AUTOSAR XML (schema 00044)
package /E40_Platform_System_SystemPackage/Components
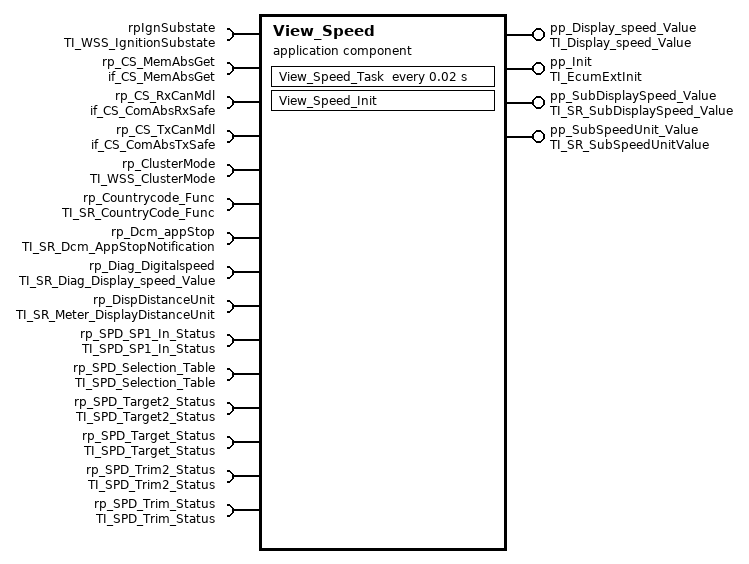
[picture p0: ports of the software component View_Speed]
  application sw component type View_Speed
    4 x provide port:
      pp_Display_speed_Value: nonqueued-sender-com-spec{data-element=Digital_Speed_Value, init-value=constant-reference=View_SpeedDigital_Speed_ValueValue0}, provided-interface=TI_Display_speed_Value
      pp_Init: server-com-spec{operation=Init, queue-length=1}, provided-interface=TI_EcumExtInit
      pp_SubDisplaySpeed_Value: nonqueued-sender-com-spec{data-element=SubDispSpeedVal, init-value=constant-reference=View_SpeedSubDispSpeedValValue0}, provided-interface=TI_SR_SubDisplaySpeed_Value
      pp_SubSpeedUnit_Value: nonqueued-sender-com-spec{data-element=SubSpeedunit, init-value=constant-reference=View_SpeedSubSpeedunitValue0}, provided-interface=TI_SR_SubSpeedUnitValue
    15 x require port:
      rpIgnSubstate: nonqueued-receiver-com-spec{data-element=IgnitionSubstate, init-value=constant-reference=View_SpeedIgnitionSubstateValue0}, required-interface=TI_WSS_IgnitionSubstate
      rp_CS_MemAbsGet: required-interface=if_CS_MemAbsGet
        required-com-specs:
          Get_BsConst_Audio_Element
          Get_BsConst_Communication_Element
          Get_BsConst_EngOffTimer_Element
          Get_BsConst_FuelGauge_Element
          Get_BsConst_OilGauge_Element
          Get_BsConst_PowerGauge_Element
          Get_BsConst_Power_Element
          Get_BsConst_RealTimeClock_Element
          Get_BsConst_ServiceReminder_Element
          Get_BsConst_SpeedoGauge_Element
          Get_BsConst_TachoGauge_Element
          Get_BsConst_TempGauge_Element
          Get_BsConst_TripComputer_Element
          Get_BsConst_Warning_Element
          Get_BsCys_Certicificate_Element
          Get_BsDiag_Dtc_Element
          Get_BsDiag_ErrorRecord_Element
          Get_BsReten_Audio_Element
          Get_BsReten_Communication_Element
          Get_BsReten_Display_Element
          Get_BsReten_Gauges_Element
          Get_BsReten_Illumination_Element
          Get_BsReten_Odometer_Element
          Get_BsReten_Personalization_Element
          Get_BsReten_Power_Element
          Get_BsReten_RealTimeClock_Element
          Get_BsReten_Tripcomputer_Element
          Get_BsReten_Warning_Element
          Get_BsRt_CusDlt_Element
          Get_BsRt_FuelGauge_Element
          Get_BsRt_Illumination_Element
          Get_BsRt_Odometer_Element
          Get_BsRt_OilGauge_Element
          Get_BsRt_Personalization_Element
          Get_BsRt_PowerGauge_Element
          Get_BsRt_RealTimeClock_Element
          Get_BsRt_SpeedoGauge_Element
          Get_BsRt_TachoGauge_Element
          Get_BsRt_TempGauge_Element
          Get_BsRt_TripComputer_Element
          Get_BsRt_Warning_Element
          Get_BsShare_EcuPartNumber_Element
          Get_BsShare_SwUpdFotaFinPrint_Element
          Get_BsShare_SwUpdFotaMode_Element
          Get_BsShare_SwUpdFotaStatus_Element
          Get_BsShare_SwUpdFotadecrypt_Element
          Get_BsShare_SwUpdReflash_Element
          Get_BsShare_VehicleConfig_Element
          Get_BsShare_VisMeet_Element
          Get_RefCys_Certicificate1_Element
          Get_RefCys_Certicificate_Element
          Get_BsShare_VisMeet_EOLEntry_Element
          Get_BsShare_AssemblyManufacturingDate
          Get_BsShare_AssemblyPlantNumber
          Get_BsShare_HWModification
          Get_BsShare_PCBSerialNumber
          Get_BsShare_ProductSerialNumber
          Get_BsShare_SMTManufacturingDate
          Get_BsShare_SMTPlantNumber
          Get_BsShare_VisteonPCBPartNumber
          Get_BsShare_VisteonPartNumber
          Get_BsConst_Temperature_Sensor_Conv_SafeCopy2
          Get_BsConst_Temperature_Sensor_Conv_SafeCopy1
          Get_BsConst_Temperature_Sensor_Conv
          Get_BsConst_Temp_Threshold_Hysteresis_Derating_SafeCopy2
          Get_BsConst_Temp_Threshold_Hysteresis_Derating_SafeCopy1
          Get_BsConst_Temp_Threshold_Hysteresis_Derating
          Get_BsConst_PWM_boost_bypass_duty_SafeCopy2
          Get_BsConst_PWM_boost_bypass_duty_SafeCopy1
          Get_BsConst_PWM_boost_bypass_duty
          Get_BsConst_PCB_Temperature_Sensor_Conv_SafeCopy2
          Get_BsConst_PCB_Temperature_Sensor_Conv_SafeCopy1
          Get_BsConst_PCB_Temperature_Sensor_Conv
          Get_BsConst_Lookup_Curve_HotSpot_Coef_Y_SafeCopy2
          Get_BsConst_Lookup_Curve_HotSpot_Coef_Y_SafeCopy1
          Get_BsConst_Lookup_Curve_HotSpot_Coef_Y
          Get_BsConst_Lookup_Curve_HotSpot_Coef_X_SafeCopy2
          Get_BsConst_Lookup_Curve_HotSpot_Coef_X_SafeCopy1
          Get_BsConst_Lookup_Curve_HotSpot_Coef_X
          Get_BsConst_Display_Illum_Max_Level_SafeCopy2
          Get_BsConst_Display_Illum_Max_Level_SafeCopy1
          Get_BsConst_Display_Illum_Max_Level
          Get_BsConst_Derating_Backlight_Disable_SafeCopy2
          Get_BsConst_Derating_Backlight_Disable_SafeCopy1
          Get_BsConst_Derating_Backlight_Disable
          Get_BsConst_Compensation_Line_Slope_m_SafeCopy2
          Get_BsConst_Compensation_Line_Slope_m_SafeCopy1
          Get_BsConst_Compensation_Line_Slope_m
          Get_BsConst_Compensation_Line_Shift_b_SafeCopy2
          Get_BsConst_Compensation_Line_Shift_b_SafeCopy1
          Get_BsConst_Compensation_Line_Shift_b
          Get_BsConst_BsConst_Illumination_ReservedByte_SafeCopy2
          Get_BsConst_BsConst_Illumination_ReservedByte_SafeCopy1
          Get_BsConst_BsConst_Illumination_ReservedByte
      rp_CS_RxCanMdl: required-interface=if_CS_ComAbsRxSafe
        required-com-specs:
          RxCan_GetSignalValue
          RxCan_GetSignalValueU8Arr
          RxCan_SetSignalInitValue
          RxCan_SetSignalInitValueU8Arr
          RxCan_SignalClearJustRcvdStatus
          RxCan_SignalGetJustRcvdStatus
          RxCan_SignalInvalidProcessingControl
          RxCan_SignalMissingProcessingControl
          RxCan_SignalNRProcessingControl
      rp_CS_TxCanMdl: required-interface=if_CS_ComAbsTxSafe
        required-com-specs:
          TxCan_ClearCanSignalTxConfirmation
          TxCan_GetCanSignalTxConfirmation
          TxCan_SetSignalFromRetentionBuffer
          TxCan_SetSignalValue
          TxCan_SetSignalValueU8Arr
      rp_ClusterMode: nonqueued-receiver-com-spec{data-element=WSSCurrentClusterMode, init-value=constant-reference=View_SpeedWSSCurrentClusterModeValue0}, required-interface=TI_WSS_ClusterMode
      rp_Countrycode_Func: nonqueued-receiver-com-spec{data-element=CountryCode_Func, init-value=constant-reference=View_SpeedCountryCode_FuncValue0}, required-interface=TI_SR_CountryCode_Func
      rp_Dcm_appStop: nonqueued-receiver-com-spec{data-element=AppId, init-value=constant-reference=View_SpeedAppIdValue0}, required-interface=TI_SR_Dcm_AppStopNotification
      rp_Diag_Digitalspeed: nonqueued-receiver-com-spec{data-element=Diag_Digital_Speed_Value, init-value=constant-reference=View_SpeedDiag_Digital_Speed_ValueValue0}, required-interface=TI_SR_Diag_Display_speed_Value
      rp_DispDistanceUnit: nonqueued-receiver-com-spec{data-element=DisplayUnit, init-value=constant-reference=View_SpeedDisplayUnitValue0}, required-interface=TI_SR_Meter_DisplayDistanceUnit
      rp_SPD_SP1_In_Status: nonqueued-receiver-com-spec{data-element=SP1_In_Status, init-value=constant-reference=View_SpeedSP1_In_StatusValue0}, required-interface=TI_SPD_SP1_In_Status
      rp_SPD_Selection_Table: nonqueued-receiver-com-spec{data-element=Speed_Selection_Table, init-value=constant-reference=View_SpeedSpeed_Selection_TableValue0}, required-interface=TI_SPD_Selection_Table
      rp_SPD_Target2_Status: nonqueued-receiver-com-spec{data-element=Spd_Target2_Status, init-value=constant-reference=View_SpeedSpd_Target2_StatusValue0}, required-interface=TI_SPD_Target2_Status
      rp_SPD_Target_Status: nonqueued-receiver-com-spec{data-element=Spd_Target_Status, init-value=constant-reference=View_SpeedSpd_Target_StatusValue0}, required-interface=TI_SPD_Target_Status
      rp_SPD_Trim2_Status: nonqueued-receiver-com-spec{data-element=Spd_Trim2_Status, init-value=constant-reference=View_SpeedSpd_Trim2_StatusValue0}, required-interface=TI_SPD_Trim2_Status
      rp_SPD_Trim_Status: nonqueued-receiver-com-spec{data-element=Spd_Trim_Status, init-value=constant-reference=View_SpeedSpd_Trim_StatusValue0}, required-interface=TI_SPD_Trim_Status
    behavior IB_View_Speed
      operation invoked event OIE_pp_Init_View_Speed_InitTrigByInit: start-on-event=View_Speed_Init, operation=pp_Init.Init
      timing event TEView_Speed_Task: start-on-event=View_Speed_Task, period=0.02
      port-api-options:
        enable-take-address=false, indirect-api=false, port=pp_Display_speed_Value
        enable-take-address=false, indirect-api=false, port=pp_Init
        enable-take-address=false, indirect-api=false, port=pp_SubDisplaySpeed_Value
        enable-take-address=false, indirect-api=false, port=pp_SubSpeedUnit_Value
        enable-take-address=false, indirect-api=false, port=rpIgnSubstate
        enable-take-address=false, indirect-api=false, port=rp_CS_MemAbsGet
        enable-take-address=false, indirect-api=false, port=rp_CS_RxCanMdl
        enable-take-address=false, indirect-api=false, port=rp_CS_TxCanMdl
        enable-take-address=false, indirect-api=false, port=rp_ClusterMode
        enable-take-address=false, indirect-api=false, port=rp_Countrycode_Func
        enable-take-address=false, indirect-api=false, port=rp_Dcm_appStop
        enable-take-address=false, indirect-api=false, port=rp_Diag_Digitalspeed
        enable-take-address=false, indirect-api=false, port=rp_DispDistanceUnit
        enable-take-address=false, indirect-api=false, port=rp_SPD_SP1_In_Status
        enable-take-address=false, indirect-api=false, port=rp_SPD_Selection_Table
        enable-take-address=false, indirect-api=false, port=rp_SPD_Target2_Status
        enable-take-address=false, indirect-api=false, port=rp_SPD_Target_Status
        enable-take-address=false, indirect-api=false, port=rp_SPD_Trim2_Status
        enable-take-address=false, indirect-api=false, port=rp_SPD_Trim_Status
      runnable View_Speed_Init: can-be-invoked-concurrently=true
      runnable View_Speed_Task: can-be-invoked-concurrently=true
        data-receive-point-by-arguments:
          12 x access:
            DRA_rpIgnSubstate_IgnitionSubstate: accessed-variable=rpIgnSubstate.IgnitionSubstate
            DRA_rp_ClusterMode_WSSCurrentClusterMode: accessed-variable=rp_ClusterMode.WSSCurrentClusterMode
            DRA_rp_Countrycode_Func_CountryCode_Func: accessed-variable=rp_Countrycode_Func.CountryCode_Func
            DRA_rp_Dcm_appStop_AppId: accessed-variable=rp_Dcm_appStop.AppId
            DRA_rp_Diag_Digitalspeed_Diag_Digital_Speed_Value: accessed-variable=rp_Diag_Digitalspeed.Diag_Digital_Speed_Value
            DRA_rp_DispDistanceUnit_DisplayUnit: accessed-variable=rp_DispDistanceUnit.DisplayUnit
            DRA_rp_SPD_SP1_In_Status_SP1_In_Status: accessed-variable=rp_SPD_SP1_In_Status.SP1_In_Status
            DRA_rp_SPD_Selection_Table_Speed_Selection_Table: accessed-variable=rp_SPD_Selection_Table.Speed_Selection_Table
            DRA_rp_SPD_Target2_Status_Spd_Target2_Status: accessed-variable=rp_SPD_Target2_Status.Spd_Target2_Status
            DRA_rp_SPD_Target_Status_Spd_Target_Status: accessed-variable=rp_SPD_Target_Status.Spd_Target_Status
            DRA_rp_SPD_Trim2_Status_Spd_Trim2_Status: accessed-variable=rp_SPD_Trim2_Status.Spd_Trim2_Status
            DRA_rp_SPD_Trim_Status_Spd_Trim_Status: accessed-variable=rp_SPD_Trim_Status.Spd_Trim_Status
        data-send-points:
          access DWA_pp_Display_speed_Value_Digital_Speed_Value: accessed-variable=pp_Display_speed_Value.Digital_Speed_Value
          access DWA_pp_SubDisplaySpeed_Value_SubDispSpeedVal: accessed-variable=pp_SubDisplaySpeed_Value.SubDispSpeedVal
          access DWA_pp_SubSpeedUnit_Value_SubSpeedunit: accessed-variable=pp_SubSpeedUnit_Value.SubSpeedunit
        108 x sync call:
          OA_rp_CS_MemAbsGet_Get_BsShare_SwUpdReflash_Element: operation=rp_CS_MemAbsGet.Get_BsShare_SwUpdReflash_Element
          OA_rp_CS_MemAbsGet_Get_BsShare_SwUpdFotaMode_Element: operation=rp_CS_MemAbsGet.Get_BsShare_SwUpdFotaMode_Element
          OA_rp_CS_MemAbsGet_Get_BsShare_SwUpdFotaFinPrint_Element: operation=rp_CS_MemAbsGet.Get_BsShare_SwUpdFotaFinPrint_Element
          OA_rp_CS_MemAbsGet_Get_BsShare_SwUpdFotaStatus_Element: operation=rp_CS_MemAbsGet.Get_BsShare_SwUpdFotaStatus_Element
          OA_rp_CS_MemAbsGet_Get_BsShare_SwUpdFotadecrypt_Element: operation=rp_CS_MemAbsGet.Get_BsShare_SwUpdFotadecrypt_Element
          OA_rp_CS_MemAbsGet_Get_BsShare_EcuPartNumber_Element: operation=rp_CS_MemAbsGet.Get_BsShare_EcuPartNumber_Element
          OA_rp_CS_MemAbsGet_Get_BsShare_VisteonPartNumber: operation=rp_CS_MemAbsGet.Get_BsShare_VisteonPartNumber
          OA_rp_CS_MemAbsGet_Get_BsShare_VisteonPCBPartNumber: operation=rp_CS_MemAbsGet.Get_BsShare_VisteonPCBPartNumber
          OA_rp_CS_MemAbsGet_Get_BsShare_ProductSerialNumber: operation=rp_CS_MemAbsGet.Get_BsShare_ProductSerialNumber
          OA_rp_CS_MemAbsGet_Get_BsShare_PCBSerialNumber: operation=rp_CS_MemAbsGet.Get_BsShare_PCBSerialNumber
          OA_rp_CS_MemAbsGet_Get_BsShare_SMTManufacturingDate: operation=rp_CS_MemAbsGet.Get_BsShare_SMTManufacturingDate
          OA_rp_CS_MemAbsGet_Get_BsShare_AssemblyManufacturingDate: operation=rp_CS_MemAbsGet.Get_BsShare_AssemblyManufacturingDate
          OA_rp_CS_MemAbsGet_Get_BsShare_SMTPlantNumber: operation=rp_CS_MemAbsGet.Get_BsShare_SMTPlantNumber
          OA_rp_CS_MemAbsGet_Get_BsShare_AssemblyPlantNumber: operation=rp_CS_MemAbsGet.Get_BsShare_AssemblyPlantNumber
          OA_rp_CS_MemAbsGet_Get_BsShare_HWModification: operation=rp_CS_MemAbsGet.Get_BsShare_HWModification
          OA_rp_CS_MemAbsGet_Get_BsShare_VisMeet_Element: operation=rp_CS_MemAbsGet.Get_BsShare_VisMeet_Element
          OA_rp_CS_MemAbsGet_Get_BsShare_VisMeet_EOLEntry_Element: operation=rp_CS_MemAbsGet.Get_BsShare_VisMeet_EOLEntry_Element
          OA_rp_CS_MemAbsGet_Get_BsShare_VehicleConfig_Element: operation=rp_CS_MemAbsGet.Get_BsShare_VehicleConfig_Element
          OA_rp_CS_MemAbsGet_Get_BsConst_SpeedoGauge_Element: operation=rp_CS_MemAbsGet.Get_BsConst_SpeedoGauge_Element
          OA_rp_CS_MemAbsGet_Get_BsConst_TachoGauge_Element: operation=rp_CS_MemAbsGet.Get_BsConst_TachoGauge_Element
          OA_rp_CS_MemAbsGet_Get_BsConst_FuelGauge_Element: operation=rp_CS_MemAbsGet.Get_BsConst_FuelGauge_Element
          OA_rp_CS_MemAbsGet_Get_BsConst_TempGauge_Element: operation=rp_CS_MemAbsGet.Get_BsConst_TempGauge_Element
          OA_rp_CS_MemAbsGet_Get_BsConst_PowerGauge_Element: operation=rp_CS_MemAbsGet.Get_BsConst_PowerGauge_Element
          OA_rp_CS_MemAbsGet_Get_BsConst_OilGauge_Element: operation=rp_CS_MemAbsGet.Get_BsConst_OilGauge_Element
          OA_rp_CS_MemAbsGet_Get_BsConst_TripComputer_Element: operation=rp_CS_MemAbsGet.Get_BsConst_TripComputer_Element
          OA_rp_CS_MemAbsGet_Get_BsConst_Audio_Element: operation=rp_CS_MemAbsGet.Get_BsConst_Audio_Element
          OA_rp_CS_MemAbsGet_Get_BsConst_Warning_Element: operation=rp_CS_MemAbsGet.Get_BsConst_Warning_Element
          OA_rp_CS_MemAbsGet_Get_BsConst_RealTimeClock_Element: operation=rp_CS_MemAbsGet.Get_BsConst_RealTimeClock_Element
          OA_rp_CS_MemAbsGet_Get_BsConst_Communication_Element: operation=rp_CS_MemAbsGet.Get_BsConst_Communication_Element
          OA_rp_CS_MemAbsGet_Get_BsConst_Power_Element: operation=rp_CS_MemAbsGet.Get_BsConst_Power_Element
          OA_rp_CS_MemAbsGet_Get_BsConst_ServiceReminder_Element: operation=rp_CS_MemAbsGet.Get_BsConst_ServiceReminder_Element
          OA_rp_CS_MemAbsGet_Get_BsConst_EngOffTimer_Element: operation=rp_CS_MemAbsGet.Get_BsConst_EngOffTimer_Element
          OA_rp_CS_MemAbsGet_Get_BsCys_Certicificate_Element: operation=rp_CS_MemAbsGet.Get_BsCys_Certicificate_Element
          OA_rp_CS_MemAbsGet_Get_RefCys_Certicificate_Element: operation=rp_CS_MemAbsGet.Get_RefCys_Certicificate_Element
          OA_rp_CS_MemAbsGet_Get_RefCys_Certicificate1_Element: operation=rp_CS_MemAbsGet.Get_RefCys_Certicificate1_Element
          OA_rp_CS_MemAbsGet_Get_BsRt_Odometer_Element: operation=rp_CS_MemAbsGet.Get_BsRt_Odometer_Element
          OA_rp_CS_MemAbsGet_Get_BsRt_SpeedoGauge_Element: operation=rp_CS_MemAbsGet.Get_BsRt_SpeedoGauge_Element
          OA_rp_CS_MemAbsGet_Get_BsRt_TachoGauge_Element: operation=rp_CS_MemAbsGet.Get_BsRt_TachoGauge_Element
          OA_rp_CS_MemAbsGet_Get_BsRt_FuelGauge_Element: operation=rp_CS_MemAbsGet.Get_BsRt_FuelGauge_Element
          OA_rp_CS_MemAbsGet_Get_BsRt_TempGauge_Element: operation=rp_CS_MemAbsGet.Get_BsRt_TempGauge_Element
          OA_rp_CS_MemAbsGet_Get_BsRt_PowerGauge_Element: operation=rp_CS_MemAbsGet.Get_BsRt_PowerGauge_Element
          OA_rp_CS_MemAbsGet_Get_BsRt_OilGauge_Element: operation=rp_CS_MemAbsGet.Get_BsRt_OilGauge_Element
          OA_rp_CS_MemAbsGet_Get_BsRt_TripComputer_Element: operation=rp_CS_MemAbsGet.Get_BsRt_TripComputer_Element
          OA_rp_CS_MemAbsGet_Get_BsRt_Warning_Element: operation=rp_CS_MemAbsGet.Get_BsRt_Warning_Element
          OA_rp_CS_MemAbsGet_Get_BsRt_RealTimeClock_Element: operation=rp_CS_MemAbsGet.Get_BsRt_RealTimeClock_Element
          OA_rp_CS_MemAbsGet_Get_BsRt_Personalization_Element: operation=rp_CS_MemAbsGet.Get_BsRt_Personalization_Element
          OA_rp_CS_MemAbsGet_Get_BsRt_Illumination_Element: operation=rp_CS_MemAbsGet.Get_BsRt_Illumination_Element
          OA_rp_CS_MemAbsGet_Get_BsRt_CusDlt_Element: operation=rp_CS_MemAbsGet.Get_BsRt_CusDlt_Element
          OA_rp_CS_MemAbsGet_Get_BsReten_Odometer_Element: operation=rp_CS_MemAbsGet.Get_BsReten_Odometer_Element
          OA_rp_CS_MemAbsGet_Get_BsReten_Gauges_Element: operation=rp_CS_MemAbsGet.Get_BsReten_Gauges_Element
          OA_rp_CS_MemAbsGet_Get_BsReten_Tripcomputer_Element: operation=rp_CS_MemAbsGet.Get_BsReten_Tripcomputer_Element
          OA_rp_CS_MemAbsGet_Get_BsReten_Illumination_Element: operation=rp_CS_MemAbsGet.Get_BsReten_Illumination_Element
          OA_rp_CS_MemAbsGet_Get_BsReten_Audio_Element: operation=rp_CS_MemAbsGet.Get_BsReten_Audio_Element
          OA_rp_CS_MemAbsGet_Get_BsReten_Warning_Element: operation=rp_CS_MemAbsGet.Get_BsReten_Warning_Element
          OA_rp_CS_MemAbsGet_Get_BsReten_RealTimeClock_Element: operation=rp_CS_MemAbsGet.Get_BsReten_RealTimeClock_Element
          OA_rp_CS_MemAbsGet_Get_BsReten_Communication_Element: operation=rp_CS_MemAbsGet.Get_BsReten_Communication_Element
          OA_rp_CS_MemAbsGet_Get_BsReten_Personalization_Element: operation=rp_CS_MemAbsGet.Get_BsReten_Personalization_Element
          OA_rp_CS_MemAbsGet_Get_BsReten_Power_Element: operation=rp_CS_MemAbsGet.Get_BsReten_Power_Element
          OA_rp_CS_MemAbsGet_Get_BsReten_Display_Element: operation=rp_CS_MemAbsGet.Get_BsReten_Display_Element
          OA_rp_CS_MemAbsGet_Get_BsDiag_ErrorRecord_Element: operation=rp_CS_MemAbsGet.Get_BsDiag_ErrorRecord_Element
          OA_rp_CS_MemAbsGet_Get_BsDiag_Dtc_Element: operation=rp_CS_MemAbsGet.Get_BsDiag_Dtc_Element
          OA_rp_CS_RxCanMdl_RxCan_GetSignalValueU8Arr: operation=rp_CS_RxCanMdl.RxCan_GetSignalValueU8Arr
          OA_rp_CS_RxCanMdl_RxCan_SetSignalInitValue: operation=rp_CS_RxCanMdl.RxCan_SetSignalInitValue
          OA_rp_CS_RxCanMdl_RxCan_SetSignalInitValueU8Arr: operation=rp_CS_RxCanMdl.RxCan_SetSignalInitValueU8Arr
          OA_rp_CS_RxCanMdl_RxCan_SignalInvalidProcessingControl: operation=rp_CS_RxCanMdl.RxCan_SignalInvalidProcessingControl
          OA_rp_CS_RxCanMdl_RxCan_SignalMissingProcessingControl: operation=rp_CS_RxCanMdl.RxCan_SignalMissingProcessingControl
          OA_rp_CS_RxCanMdl_RxCan_SignalNRProcessingControl: operation=rp_CS_RxCanMdl.RxCan_SignalNRProcessingControl
          OA_rp_CS_RxCanMdl_RxCan_SignalGetJustRcvdStatus: operation=rp_CS_RxCanMdl.RxCan_SignalGetJustRcvdStatus
          OA_rp_CS_RxCanMdl_RxCan_SignalClearJustRcvdStatus: operation=rp_CS_RxCanMdl.RxCan_SignalClearJustRcvdStatus
          OA_rp_CS_RxCanMdl_RxCan_GetSignalValue: operation=rp_CS_RxCanMdl.RxCan_GetSignalValue
          OA_rp_CS_TxCanMdl_TxCan_ClearCanSignalTxConfirmation: operation=rp_CS_TxCanMdl.TxCan_ClearCanSignalTxConfirmation
          OA_rp_CS_TxCanMdl_TxCan_GetCanSignalTxConfirmation: operation=rp_CS_TxCanMdl.TxCan_GetCanSignalTxConfirmation
          OA_rp_CS_TxCanMdl_TxCan_SetSignalFromRetentionBuffer: operation=rp_CS_TxCanMdl.TxCan_SetSignalFromRetentionBuffer
          OA_rp_CS_TxCanMdl_TxCan_SetSignalValue: operation=rp_CS_TxCanMdl.TxCan_SetSignalValue
          OA_rp_CS_TxCanMdl_TxCan_SetSignalValueU8Arr: operation=rp_CS_TxCanMdl.TxCan_SetSignalValueU8Arr
          OA_rp_CS_MemAbsGet_Get_BsConst_Compensation_Line_Slope_m: operation=rp_CS_MemAbsGet.Get_BsConst_Compensation_Line_Slope_m
          OA_rp_CS_MemAbsGet_Get_BsConst_Compensation_Line_Shift_b: operation=rp_CS_MemAbsGet.Get_BsConst_Compensation_Line_Shift_b
          OA_rp_CS_MemAbsGet_Get_BsConst_Lookup_Curve_HotSpot_Coef_X: operation=rp_CS_MemAbsGet.Get_BsConst_Lookup_Curve_HotSpot_Coef_X
          OA_rp_CS_MemAbsGet_Get_BsConst_Lookup_Curve_HotSpot_Coef_Y: operation=rp_CS_MemAbsGet.Get_BsConst_Lookup_Curve_HotSpot_Coef_Y
          OA_rp_CS_MemAbsGet_Get_BsConst_Temp_Threshold_Hysteresis_Derating: operation=rp_CS_MemAbsGet.Get_BsConst_Temp_Threshold_Hysteresis_Derating
          OA_rp_CS_MemAbsGet_Get_BsConst_Derating_Backlight_Disable: operation=rp_CS_MemAbsGet.Get_BsConst_Derating_Backlight_Disable
          OA_rp_CS_MemAbsGet_Get_BsConst_Temperature_Sensor_Conv: operation=rp_CS_MemAbsGet.Get_BsConst_Temperature_Sensor_Conv
          OA_rp_CS_MemAbsGet_Get_BsConst_PCB_Temperature_Sensor_Conv: operation=rp_CS_MemAbsGet.Get_BsConst_PCB_Temperature_Sensor_Conv
          OA_rp_CS_MemAbsGet_Get_BsConst_Display_Illum_Max_Level: operation=rp_CS_MemAbsGet.Get_BsConst_Display_Illum_Max_Level
          OA_rp_CS_MemAbsGet_Get_BsConst_PWM_boost_bypass_duty: operation=rp_CS_MemAbsGet.Get_BsConst_PWM_boost_bypass_duty
          OA_rp_CS_MemAbsGet_Get_BsConst_BsConst_Illumination_ReservedByte: operation=rp_CS_MemAbsGet.Get_BsConst_BsConst_Illumination_ReservedByte
          OA_rp_CS_MemAbsGet_Get_BsConst_Compensation_Line_Slope_m_SafeCopy1: operation=rp_CS_MemAbsGet.Get_BsConst_Compensation_Line_Slope_m_SafeCopy1
          OA_rp_CS_MemAbsGet_Get_BsConst_Compensation_Line_Shift_b_SafeCopy1: operation=rp_CS_MemAbsGet.Get_BsConst_Compensation_Line_Shift_b_SafeCopy1
          OA_rp_CS_MemAbsGet_Get_BsConst_Lookup_Curve_HotSpot_Coef_X_SafeCopy1: operation=rp_CS_MemAbsGet.Get_BsConst_Lookup_Curve_HotSpot_Coef_X_SafeCopy1
          OA_rp_CS_MemAbsGet_Get_BsConst_Lookup_Curve_HotSpot_Coef_Y_SafeCopy1: operation=rp_CS_MemAbsGet.Get_BsConst_Lookup_Curve_HotSpot_Coef_Y_SafeCopy1
          OA_rp_CS_MemAbsGet_Get_BsConst_Temp_Threshold_Hysteresis_Derating_SafeCopy1: operation=rp_CS_MemAbsGet.Get_BsConst_Temp_Threshold_Hysteresis_Derating_SafeCopy1
          OA_rp_CS_MemAbsGet_Get_BsConst_Derating_Backlight_Disable_SafeCopy1: operation=rp_CS_MemAbsGet.Get_BsConst_Derating_Backlight_Disable_SafeCopy1
          OA_rp_CS_MemAbsGet_Get_BsConst_Temperature_Sensor_Conv_SafeCopy1: operation=rp_CS_MemAbsGet.Get_BsConst_Temperature_Sensor_Conv_SafeCopy1
          OA_rp_CS_MemAbsGet_Get_BsConst_PCB_Temperature_Sensor_Conv_SafeCopy1: operation=rp_CS_MemAbsGet.Get_BsConst_PCB_Temperature_Sensor_Conv_SafeCopy1
          OA_rp_CS_MemAbsGet_Get_BsConst_Display_Illum_Max_Level_SafeCopy1: operation=rp_CS_MemAbsGet.Get_BsConst_Display_Illum_Max_Level_SafeCopy1
          OA_rp_CS_MemAbsGet_Get_BsConst_PWM_boost_bypass_duty_SafeCopy1: operation=rp_CS_MemAbsGet.Get_BsConst_PWM_boost_bypass_duty_SafeCopy1
          OA_rp_CS_MemAbsGet_Get_BsConst_BsConst_Illumination_ReservedByte_SafeCopy1: operation=rp_CS_MemAbsGet.Get_BsConst_BsConst_Illumination_ReservedByte_SafeCopy1
          OA_rp_CS_MemAbsGet_Get_BsConst_Compensation_Line_Slope_m_SafeCopy2: operation=rp_CS_MemAbsGet.Get_BsConst_Compensation_Line_Slope_m_SafeCopy2
          OA_rp_CS_MemAbsGet_Get_BsConst_Compensation_Line_Shift_b_SafeCopy2: operation=rp_CS_MemAbsGet.Get_BsConst_Compensation_Line_Shift_b_SafeCopy2
          OA_rp_CS_MemAbsGet_Get_BsConst_Lookup_Curve_HotSpot_Coef_X_SafeCopy2: operation=rp_CS_MemAbsGet.Get_BsConst_Lookup_Curve_HotSpot_Coef_X_SafeCopy2
          OA_rp_CS_MemAbsGet_Get_BsConst_Lookup_Curve_HotSpot_Coef_Y_SafeCopy2: operation=rp_CS_MemAbsGet.Get_BsConst_Lookup_Curve_HotSpot_Coef_Y_SafeCopy2
          OA_rp_CS_MemAbsGet_Get_BsConst_Temp_Threshold_Hysteresis_Derating_SafeCopy2: operation=rp_CS_MemAbsGet.Get_BsConst_Temp_Threshold_Hysteresis_Derating_SafeCopy2
          OA_rp_CS_MemAbsGet_Get_BsConst_Derating_Backlight_Disable_SafeCopy2: operation=rp_CS_MemAbsGet.Get_BsConst_Derating_Backlight_Disable_SafeCopy2
          OA_rp_CS_MemAbsGet_Get_BsConst_Temperature_Sensor_Conv_SafeCopy2: operation=rp_CS_MemAbsGet.Get_BsConst_Temperature_Sensor_Conv_SafeCopy2
          OA_rp_CS_MemAbsGet_Get_BsConst_PCB_Temperature_Sensor_Conv_SafeCopy2: operation=rp_CS_MemAbsGet.Get_BsConst_PCB_Temperature_Sensor_Conv_SafeCopy2
          OA_rp_CS_MemAbsGet_Get_BsConst_Display_Illum_Max_Level_SafeCopy2: operation=rp_CS_MemAbsGet.Get_BsConst_Display_Illum_Max_Level_SafeCopy2
          OA_rp_CS_MemAbsGet_Get_BsConst_PWM_boost_bypass_duty_SafeCopy2: operation=rp_CS_MemAbsGet.Get_BsConst_PWM_boost_bypass_duty_SafeCopy2
          OA_rp_CS_MemAbsGet_Get_BsConst_BsConst_Illumination_ReservedByte_SafeCopy2: operation=rp_CS_MemAbsGet.Get_BsConst_BsConst_Illumination_ReservedByte_SafeCopy2
  swc implementation IMPL_View_Speed: behavior=IB_View_Speed
